VERSION ""

NS_ :

BS_:

BU_: Sensor

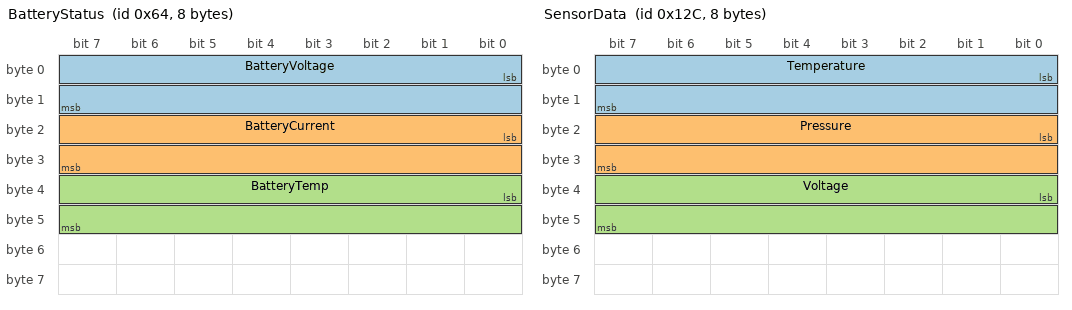
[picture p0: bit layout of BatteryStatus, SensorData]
BO_ 100 BatteryStatus: 8 Sensor
 SG_ BatteryVoltage : 0|16@1+ (0.01,0) [0|655.35] "V" Vector__XXX
 SG_ BatteryCurrent : 16|16@1- (0.1,0) [-3276.8|3276.7] "A" Vector__XXX
 SG_ BatteryTemp : 32|16@1- (0.1,0) [-3276.8|3276.7] "C" Vector__XXX

BO_ 200 MotorStatus: 8 Sensor
 SG_ MotorSpeed : 0|16@1- (1,0) [-32768|32767] "rpm" Vector__XXX
 SG_ MotorTorque : 16|16@1- (0.1,0) [-3276.8|3276.7] "Nm" Vector__XXX

BO_ 300 SensorData: 8 Sensor
 SG_ Temperature : 0|16@1- (0.1,0) [-3276.8|3276.7] "C" Vector__XXX
 SG_ Pressure : 16|16@1+ (0.01,0) [0|655.35] "bar" Vector__XXX
 SG_ Voltage : 32|16@1+ (0.01,0) [0|655.35] "V" Vector__XXX

CM_ SG_ 100 BatteryVoltage "topic:Battery/Module1/Voltage";
CM_ SG_ 100 BatteryCurrent "topic:Battery/Module1/Current";
CM_ SG_ 100 BatteryTemp "topic:Battery/Module1/Temperature";
CM_ SG_ 200 MotorSpeed "topic:Motor/Controller/Speed";
CM_ SG_ 200 MotorTorque "topic:Motor/Controller/Torque";
CM_ SG_ 300 Temperature "topic:Sensor/Thermal/Temperature";
CM_ SG_ 300 Pressure "topic:Sensor/Hydraulic/Pressure";
CM_ SG_ 300 Voltage "topic:Sensor/Electrical/Voltage";
